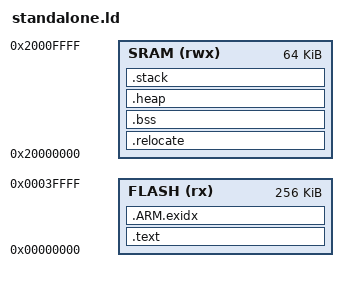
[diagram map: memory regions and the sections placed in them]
/******************************************************************************
 *
 * standalone.ld - Linker script for applications using startup.c and
 *                 DriverLib.
 *
 * Copyright (c) 2005-2007 Luminary Micro, Inc.  All rights reserved.
 * 
 * Software License Agreement
 * 
 * Luminary Micro, Inc. (LMI) is supplying this software for use solely and
 * exclusively on LMI's microcontroller products.
 * 
 * The software is owned by LMI and/or its suppliers, and is protected under
 * applicable copyright laws.  All rights are reserved.  Any use in violation
 * of the foregoing restrictions may subject the user to criminal sanctions
 * under applicable laws, as well as to civil liability for the breach of the
 * terms and conditions of this license.
 * 
 * THIS SOFTWARE IS PROVIDED "AS IS".  NO WARRANTIES, WHETHER EXPRESS, IMPLIED
 * OR STATUTORY, INCLUDING, BUT NOT LIMITED TO, IMPLIED WARRANTIES OF
 * MERCHANTABILITY AND FITNESS FOR A PARTICULAR PURPOSE APPLY TO THIS SOFTWARE.
 * LMI SHALL NOT, IN ANY CIRCUMSTANCES, BE LIABLE FOR SPECIAL, INCIDENTAL, OR
 * CONSEQUENTIAL DAMAGES, FOR ANY REASON WHATSOEVER.
 * 
 * This is part of revision 1392 of the Stellaris Peripheral Driver Library.
 *
 *****************************************************************************/

STACK_SIZE = 1K;
HEAP_SIZE = 32K;

MEMORY
{
    FLASH (rx) : ORIGIN = 0x00000000, LENGTH = 256K
    SRAM (rwx) : ORIGIN = 0x20000000, LENGTH = 64K
}

/* Section Definitions */
SECTIONS
{
    .text :
    {
        . = ALIGN(4);
        _sfixed = .;
        KEEP(*(.isr_vector))
        
        . = ALIGN(4);
        _stext = .;
        *(.text .text.* .gnu.linkonce.t.*)
        *(.glue_7t) *(.glue_7)
        *(.rodata .rodata* .gnu.linkonce.r.*)
        *(.ARM.extab* .gnu.linkonce.armextab.*)

        /* Support C constructors, and C destructors in both user code
           and the C library. This also provides support for C++ code. */
        . = ALIGN(4);
        KEEP(*(.init))
        . = ALIGN(4);
        __preinit_array_start = .;
        KEEP (*(.preinit_array))
        __preinit_array_end = .;

        . = ALIGN(4);
        __init_array_start = .;
        KEEP (*(SORT(.init_array.*)))
        KEEP (*(.init_array))
        __init_array_end = .;

        . = ALIGN(4);
        KEEP (*crtbegin.o(.ctors))
        KEEP (*(EXCLUDE_FILE (*crtend.o) .ctors))
        KEEP (*(SORT(.ctors.*)))
        KEEP (*crtend.o(.ctors))

        . = ALIGN(4);
        KEEP(*(.fini))

        . = ALIGN(4);
        __fini_array_start = .;
        KEEP (*(.fini_array))
        KEEP (*(SORT(.fini_array.*)))
        __fini_array_end = .;

        KEEP (*crtbegin.o(.dtors))
        KEEP (*(EXCLUDE_FILE (*crtend.o) .dtors))
        KEEP (*(SORT(.dtors.*)))
        KEEP (*crtend.o(.dtors))

        . = ALIGN(4);
        _efixed = .;            /* End of text section */
    } > FLASH

    /* .ARM.exidx is sorted, so has to go in its own output section.  */
    PROVIDE_HIDDEN (__exidx_start = .);
    .ARM.exidx :
    {
      *(.ARM.exidx* .gnu.linkonce.armexidx.*)
    } > FLASH
    PROVIDE_HIDDEN (__exidx_end = .);

    . = ALIGN(4);
    _etext = .;

    .relocate : AT (_etext)
    {
        . = ALIGN(4);
        _data = .;
        *(.data .data.*);
        _edata = .;
    } > SRAM

    /* .bss section which is used for uninitialized data */
    .bss (NOLOAD) :
    {
        . = ALIGN(4);
        _bss = . ;
        _szero = .;
        *(.bss .bss.*)
        *(COMMON)
        . = ALIGN(4);
        _ebss = . ;
        _ezero = .;
    } > SRAM

    /* heap section */
    .heap (NOLOAD):
    {
        . = ALIGN(8);
         __HeapBase = .;
        . = . + HEAP_SIZE;
        . = ALIGN(8);
        __HeapLimit = .;
    } > SRAM

    /* stack section */
    .stack (NOLOAD):
    {
        . = ALIGN(8);
         _sstack = .;
        . = . + STACK_SIZE;
        . = ALIGN(8);
        _estack = .;
    } > SRAM

    . = ALIGN(4);
    _end = . ;
    
    /DISCARD/ :
    {
        *(.eh_frame)
    }
}
